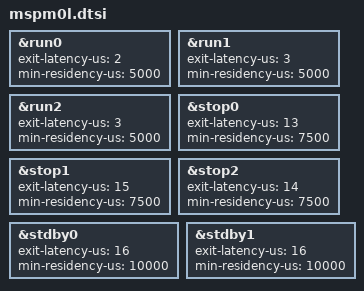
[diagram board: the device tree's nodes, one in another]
/*
 * Copyright (c) 2026 Texas Instruments
 * Copyright (c) 2025 Linumiz GmbH
 *
 * SPDX-License-Identifier: Apache-2.0
 */

#include <ti/mspm0/mspm0.dtsi>

&run0 {
	exit-latency-us = <2>; /* 1.5us */
	min-residency-us = <5000>;
};

&run1 {
	exit-latency-us = <3>; /* 2.1us */
	min-residency-us = <5000>;
};

&run2 {
	exit-latency-us = <3>; /* 2.5us */
	min-residency-us = <5000>;
};

&stop0 {
	exit-latency-us = <13>; /* 12.5us */
	min-residency-us = <7500>;
};

&stop1 {
	exit-latency-us = <15>; /* 14.6us */
	min-residency-us = <7500>;
};

&stop2 {
	exit-latency-us = <14>; /* 13.5us */
	min-residency-us = <7500>;
};

&stdby0 {
	exit-latency-us = <16>; /* 15.7us */
	min-residency-us = <10000>;
};

&stdby1 {
	exit-latency-us = <16>; /* 15.7us */
	min-residency-us = <10000>;
};
